# RL6678_IP_SVD register map
Vendor: Realtek
Registers are 32-bit, read-write, reset 0x0 unless marked. A register's access mark holds for its fields unless they carry their own. Offsets are from the block's base; [hi:lo] are bit positions; {n}, {i} and the like mark numbered series.

## PAGE0
Base 0x40000000
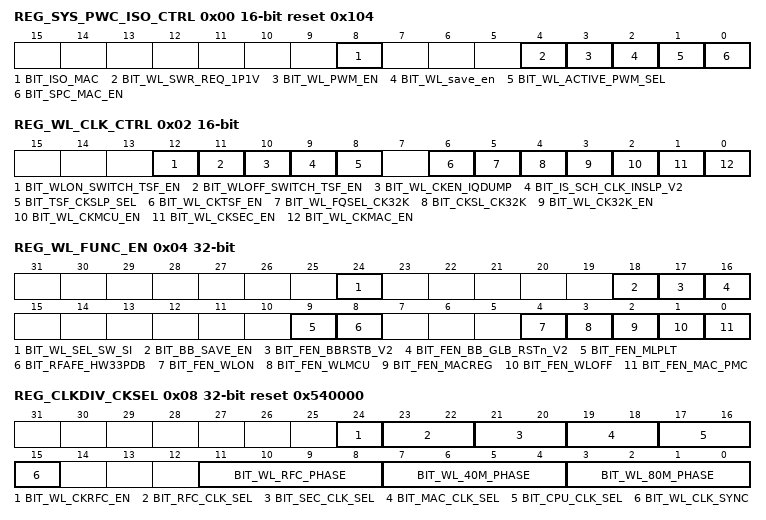
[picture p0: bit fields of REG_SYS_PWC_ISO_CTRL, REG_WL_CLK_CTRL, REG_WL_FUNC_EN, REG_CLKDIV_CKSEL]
0x00 REG_SYS_PWC_ISO_CTRL 16-bit reset 0x104
  [8] BIT_ISO_MAC — Isolation control for MAC, 1: isolation; 0: attach
  [4] BIT_WL_SWR_REQ_1P1V — 1: wl request switch SWR vlotage to 1.1V 0: wl request switch SWR vlotage to 0.9V
  [3] BIT_WL_PWM_EN — 1:WL request switch to PWM mode 0:WL request switch to PFM mode
  [2] BIT_WL_save_en — 1 to 0:gen req to restore register in power on flow 1:gen req to backup register in power on flow
  [1] BIT_WL_ACTIVE_PWM_SEL — ECO ADD. 1: wl request SWR PWM mode when eqit LPS
  [0] BIT_SPC_MAC_EN — 1: Enable WLOFF power cut
0x02 REG_WL_CLK_CTRL 16-bit access per field
  [12] BIT_WLON_SWITCH_TSF_EN rw — enable wlpmc switch TSF clock to MAC clock
  [11] BIT_WLOFF_SWITCH_TSF_EN rw — enable wlpmc switch TSF clock to 32K clock
  [10] BIT_WL_CKEN_IQDUMP rw — 0: disable clock for iqdump (LA MODE) 1: enable clock for iqdump (LA MODE) same clock source as security clock
  [9] BIT_IS_SCH_CLK_INSLP_V2 ro — WL TSF clock status: 0: MAC clock 1: 32K clock
  [8] BIT_TSF_CKSLP_SEL rw — 1: TSF clock switch to 32.768KHz; 0: TSF clock switch to MAC clock
  [6] BIT_WL_CKTSF_EN rw — 1: enable tsf clock; 0: gated
  [5] BIT_WL_FQSEL_CK32K rw — 1:32K frequency select 32.768KHz 0:32K frequency select 32KHz
  [4] BIT_CKSL_CK32K rw — 1:select MAC internal 32K clk, 0:select MAC external 32K clk
  [3] BIT_WL_CK32K_EN rw — 1: enable 32k clock; 0: gated
  [2] BIT_WL_CKMCU_EN rw — 1: enable MCU engine clock; 0: gated
  [1] BIT_WL_CKSEC_EN rw — 1: enable MAC security engine clock; 0: gated
  [0] BIT_WL_CKMAC_EN rw — 1: enable MAC clock; 0: gated
0x04 REG_WL_FUNC_EN access per field
  [24] BIT_WL_SEL_SW_SI rw — indicate SW use indirect path to access WLRFC register
  [18] BIT_BB_SAVE_EN rw — 1 to 0:gen req to restore register in power on flow 1:gen req to backup register in power on flow
  [17] BIT_FEN_BBRSTB_V2 rw — When this bit is set to "0", CCK and OFDM are disabled, and clock are gated. Otherwise, CCK and OFDM are enabled.
  [16] BIT_FEN_BB_GLB_RSTn_V2 rw — When this bit is set to "0", whole BB is reset. When this bit is set, BB is enabled.
  [9] BIT_FEN_MLPLT rw
  [8] BIT_RFAFE_HW33PDB rw
  [4] BIT_FEN_WLON rw — 1: enable WL partial ON; 0: reset
  [3] BIT_FEN_WLMCU rw — 1: enable WLMCU; 0: reset
  [2] BIT_FEN_MACREG rw — 1: enable MAC REG; 0: reset
  [1] BIT_FEN_WLOFF rw — 1: enable WLOFF; 0: reset
  [0] BIT_FEN_MAC_PMC rw — 1: enable MAC PMC; 0: reset
0x08 REG_CLKDIV_CKSEL reset 0x540000
  [24] BIT_WL_CKRFC_EN — 1: enable WLRFC clock; 0: gated
  [23:22] BIT_RFC_CLK_SEL — 11/10:40M 01:80M 00:160M
  [21:20] BIT_SEC_CLK_SEL — 11/10:40M 01:80M 00:160M
  [19:18] BIT_MAC_CLK_SEL — 11/10:20M 01:40M 00:80M
  [17:16] BIT_CPU_CLK_SEL
  [15] BIT_WL_CLK_SYNC — 1: sync 40M/80M clock phase with PLL
  [11:8] BIT_WL_RFC_PHASE — 80M WLRFC clock phase control
  [7:4] BIT_WL_40M_PHASE — 40M MAC clock phase control
  [3:0] BIT_WL_80M_PHASE — 80M security clock phase control
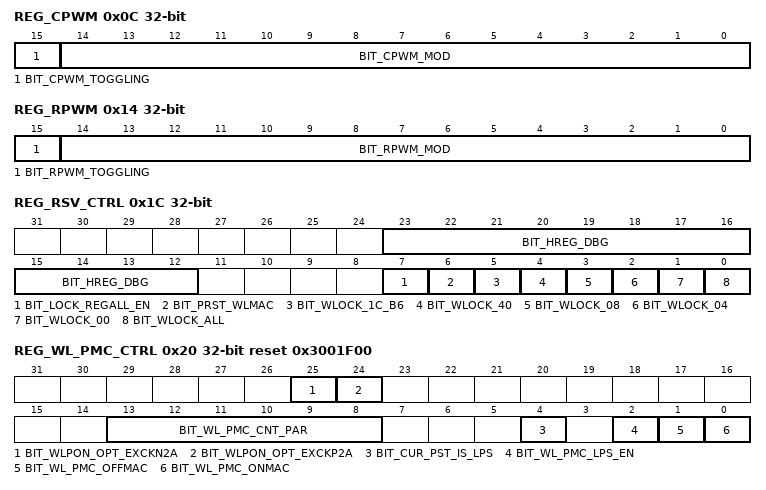
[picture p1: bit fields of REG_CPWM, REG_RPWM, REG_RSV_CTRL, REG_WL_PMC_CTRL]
0x0C REG_CPWM
  [15] BIT_CPWM_TOGGLING — Toggling bit : one bit sequence number bit. When this bit is toggled, interrupt is send to HISR.CPWMINT.
  [14:0] BIT_CPWM_MOD — The current power mode index.
0x14 REG_RPWM — register for hrpwm
  [15] BIT_RPWM_TOGGLING — Toggling bit : one bit sequence number bit. When this bit is toggled, interrupt is send to FISR.RPWMINT.
  [14:0] BIT_RPWM_MOD — The current power mode index.
0x1C REG_RSV_CTRL access per field
  [23:12] BIT_HREG_DBG ro — HREG Access Debug information
  [7] BIT_LOCK_REGALL_EN rw — 1:Enable 'Locked All' setting by Hardware, 0: Hardware Enable 'Locked All' denied.
  [6] BIT_PRST_WLMAC rw
  [5] BIT_WLOCK_1C_B6 rw — 1:Register Write Locked, 0: Register Accessible by SW/FW (offset:0x001C[6])
  [4] BIT_WLOCK_40 rw — 1:Register Write Locked, 0: Register Accessible by SW/FW (offset:0x0040h~0x0043h)
  [3] BIT_WLOCK_08 rw — 1:Register Write Locked, 0: Register Accessible by SW/FW (offset:0x0008h~0x000Bh)
  [2] BIT_WLOCK_04 rw — 1:Register Write Locked, 0: Register Accessible by SW/FW (offset:0x0004h~0x0007h)
  [1] BIT_WLOCK_00 rw — 1:Register Write Locked, 0: Register Accessible by SW/FW (offset:0x0000h~0x0003h)
  [0] BIT_WLOCK_ALL rw — 1:Register Write Locked, 0: Register Accessible by SW/FW (offset:0x0000h~0x00FFh)
0x20 REG_WL_PMC_CTRL access per field reset 0x3001F00
  [25] BIT_WLPON_OPT_EXCKN2A rw
  [24] BIT_WLPON_OPT_EXCKP2A rw — PON option to enable AFE clock
  [13:8] BIT_WL_PMC_CNT_PAR rw — WL PMC FSM counting unit.
  [4] BIT_CUR_PST_IS_LPS ro — indicate current WL power status is LPS mode
  [2] BIT_WL_PMC_LPS_EN rw — Inform WLAN PMC FSM to enter LPS mode. (auto clear when ready)
  [1] BIT_WL_PMC_OFFMAC rw — Inform WLAN PMC FSM to power OFF mode, include clock, isolation, power control for MAC only (clear when Power Ready)
  [0] BIT_WL_PMC_ONMAC rw — Inform WLAN PMC FSM to power On mode, include clock, isolation, power control for MAC only (clear when Power Ready)
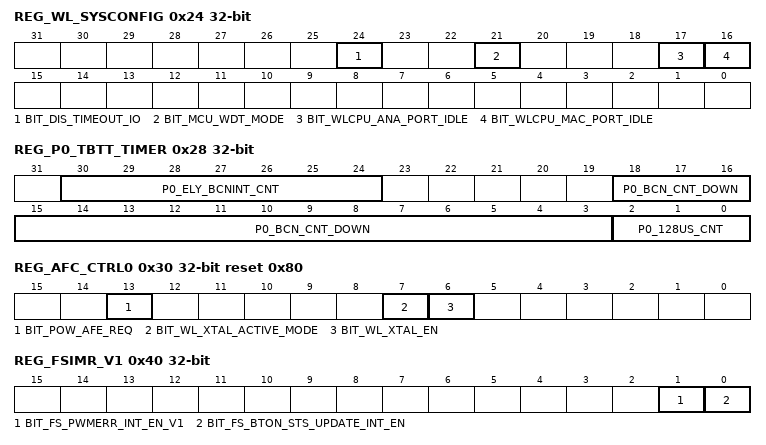
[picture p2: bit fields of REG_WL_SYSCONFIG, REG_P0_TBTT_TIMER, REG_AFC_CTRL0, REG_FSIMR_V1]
0x24 REG_WL_SYSCONFIG access per field
  [24] BIT_DIS_TIMEOUT_IO rw — Disabled timeout of IO wrapper
  [21] BIT_MCU_WDT_MODE rw
  [17] BIT_WLCPU_ANA_PORT_IDLE ro
  [16] BIT_WLCPU_MAC_PORT_IDLE ro
0x28 REG_P0_TBTT_TIMER ro
  [30:24] P0_ELY_BCNINT_CNT — Unit: bcn_space the total time to next specified TBTT is (new_ely_agg_cnt - 1) * r_bcn_space(0x554) + (beacon_cnt_down - 1)* 1ms + (cnt_128us + 1)* 128us
  [18:3] P0_BCN_CNT_DOWN — Unit: 1ms beacon_cnt_down - 1
  [2:0] P0_128US_CNT — Unit: 128us
0x30 REG_AFC_CTRL0 reset 0x80
  [13] BIT_POW_AFE_REQ — AFE power on request to afe_ctrl 1:request to turn on AFE pwr 0:turn off AFE pwr
  [7] BIT_WL_XTAL_ACTIVE_MODE — 1:WL request XTAL to enter active mode 0:WL request XTAL to enter LPS mode
  [6] BIT_WL_XTAL_EN — 1:WL enable XTAL 0:WL disable XTAL
0x40 REG_FSIMR_V1
  [1] BIT_FS_PWMERR_INT_EN_V1 — Enable MCU Access Error interrupt source(TIE0)
  [0] BIT_FS_BTON_STS_UPDATE_INT_EN — BTON status update interrupt When 0x78[31] toggled, this interrupt is issue to indicate the status updated.
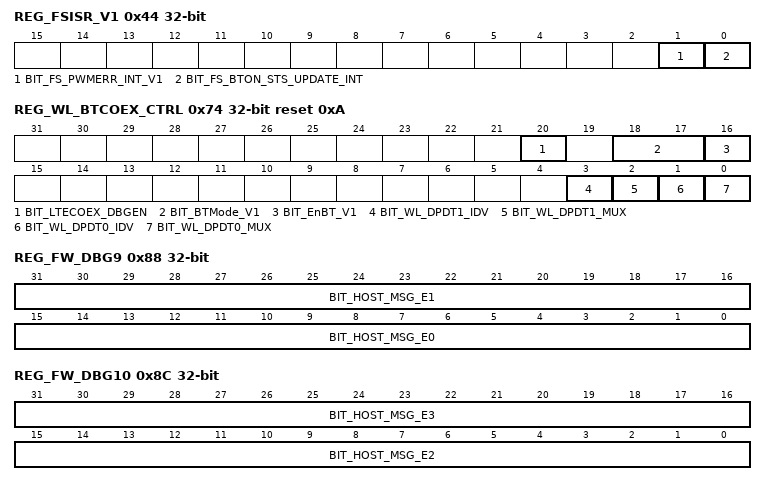
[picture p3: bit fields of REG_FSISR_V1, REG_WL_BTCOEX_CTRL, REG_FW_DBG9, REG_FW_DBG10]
0x44 REG_FSISR_V1 ro
  [1] BIT_FS_PWMERR_INT_V1 — MCU Access Error interrupt source Write 1 clear
  [0] BIT_FS_BTON_STS_UPDATE_INT — BTON status update interrupt When 0x78[31] toggled, this interrupt is issue to indicate the status updated.
0x48 TXDMA_H2C_RD_POINTER ro
  [17:0] tde_h2c_rd_addr — not used in amd2
0x4C TXDMA_H2C_WR_POINTER ro
  [17:0] tde_h2c_wr_addr — not used in amd2
{0x50+4i} REG_FW_DBG{i} (i=0..7)
  [31:0] BIT_FW_DBG{i} — fw debug{i}
0x70 REG_WL_PIN_FUNC_CTRL0
  [31:24] BIT_WL_DBG_SEL — WL debug select
0x74 REG_WL_BTCOEX_CTRL reset 0xA
  [20] BIT_LTECOEX_DBGEN
  [18:17] BIT_BTMode_V1 — Bluetooth Mode
  [16] BIT_EnBT_V1 — Enable PTA ( from BT side)
  [3] BIT_WL_DPDT1_IDV
  [2] BIT_WL_DPDT1_MUX
  [1] BIT_WL_DPDT0_IDV
  [0] BIT_WL_DPDT0_MUX
0x78 REG_SCOREBOARD_RD_BT2WL ro
  [30:0] BIT_RD_BT2WL_INFO — Read Data : WL TO BT INFO, WLON Status Report
0x7C REG_DBG_PORT_REG ro
  [31:0] BIT_DEBUG_ST — Debug signals, sel by 70[31:24]
0x80 REG_WL_MCUFW_CTRL
  [15] BIT_FW_INIT_RDY — CPU fw initialize ready, set by CPU
0x84 REG_FW_DBG8
  [31:0] BIT_BLK_TST — fw debug8
0x88 REG_FW_DBG9
  [31:16] BIT_HOST_MSG_E1 — User Defined Message
  [15:0] BIT_HOST_MSG_E0 — User Defined Message
0x8C REG_FW_DBG10
  [31:16] BIT_HOST_MSG_E3 — User Defined Message
  [15:0] BIT_HOST_MSG_E2 — User Defined Message
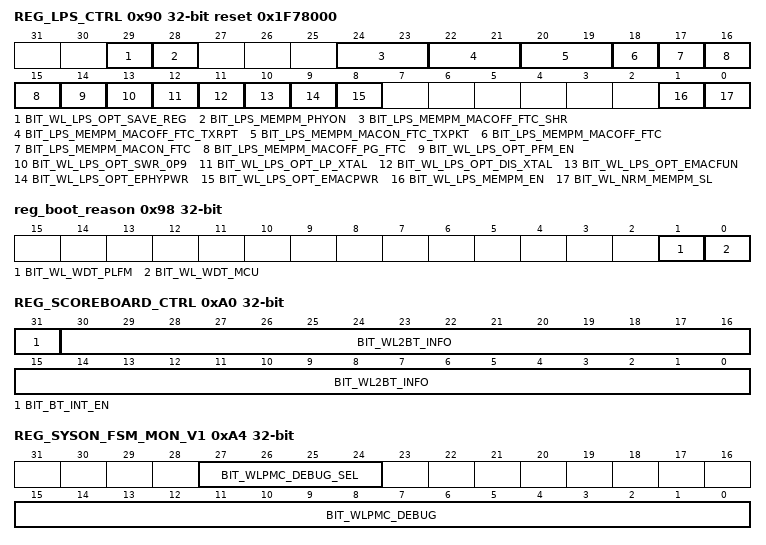
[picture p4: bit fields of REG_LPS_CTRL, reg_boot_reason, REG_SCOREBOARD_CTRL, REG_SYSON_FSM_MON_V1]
0x90 REG_LPS_CTRL access per field reset 0x1F78000
  [29] BIT_WL_LPS_OPT_SAVE_REG rw — LPS option to save retention FF 1: enable request to save retention FF 0: disable request to save retention FF
  [28] BIT_LPS_MEMPM_PHYON rw
  [24:23] BIT_LPS_MEMPM_MACOFF_FTC_SHR rw — MAC OFF FTC memory power mode when enable LPS memory power mode(for rxpktbuf/ txpktbuf low 24k[SHARE with system]) 00 : normal 01 : NAP 10 : RET 11 : SLP
  [22:21] BIT_LPS_MEMPM_MACOFF_FTC_TXRPT rw — MAC OFF FTC memory power mode when enable LPS memory power mode (for txrptbuf) 00 : normal 01 : NAP 10 : RET 11 : SLP
  [20:19] BIT_LPS_MEMPM_MACON_FTC_TXPKT rw — MAC ON FTC memory power mode when enable LPS memory power mode (for txpktbuf high 8k) 00 : normal 01 : NAP 10 : RET 11 : SLP
  [18] BIT_LPS_MEMPM_MACOFF_FTC rw — MAC OFF FTC memory power mode when enable LPS memory power mode (for txllt/rc4/txoqt/keysrch/rxfifo/txfifo/rxbacam/dmafifo/txpwr_rate/txpwr_macid/txpwr_usrlist/txpwr_srpwr/txpwr_rulim) 0 : normal 1 : NAP
  [17] BIT_LPS_MEMPM_MACON_FTC rw — MAC ON FTC memory power mode when enable LPS memory power mode(not used ) 0 : normal 1 : NAP
  [16:15] BIT_LPS_MEMPM_MACOFF_PG_FTC rw — MAC OFF FTC memory power mode when enable LPS memory power mode(for zgb_txbuf/zgb_rxbuf/rxcsibuf/phystsbuf) 00 : normal 01 : NAP 10 : RET 11 : SLP
  [14] BIT_WL_LPS_OPT_PFM_EN rw — LPS option to switch to PFM mode 1: set to PFM mode 0: stay in PWM mode
  [13] BIT_WL_LPS_OPT_SWR_0P9 rw — LPS option to set SWR voltage 0.9V 1: set SWR voltage 0.9V 0: set SWR voltage 1.1V
  [12] BIT_WL_LPS_OPT_LP_XTAL rw — LPS option to set XTAL low power mode when enable XTAL 1: set XTAL low power mode 0: set XTAL active mode
  [11] BIT_WL_LPS_OPT_DIS_XTAL rw — LPS option to disable XTAL 1: disable XTAL 0: enable XTAL
  [10] BIT_WL_LPS_OPT_EMACFUN rw — LPS option to reset WL MAC OFF block when enable WL MAC OFF power 1: not reset WL MAC OFF block 0: reset WL MAC OFF block
  [9] BIT_WL_LPS_OPT_EPHYPWR rw — LPS option to enable WL BB block power 1: Enable WL BB block power 0: Disable WL BB block power
  [8] BIT_WL_LPS_OPT_EMACPWR rw — LPS option to enable WL MAC OFF block power 1: Enable WL MAC OFF block power 0: Disable WL MAC OFF block power
  [1] BIT_WL_LPS_MEMPM_EN rw — enable LPS memory power mode control
  [0] BIT_WL_NRM_MEMPM_SL rw — MAC memory power mode when BIT_WL_LPS_MEMPM_EN is 0, 0 : Normal 1 : SD
0x94 REG_FW_DBG11
  [31:0] BIT_FW_DBG11 — fw debug11
0x98 reg_boot_reason
  [1] BIT_WL_WDT_PLFM, [0] BIT_WL_WDT_MCU
0xA0 REG_SCOREBOARD_CTRL access per field
  [31] BIT_BT_INT_EN wo — For WL, write 1 to issue interrupt 1 : Issue one INT to BT 0 : Don't care
  [30:0] BIT_WL2BT_INFO rw — WLON Status Report TO BTON
0xA4 REG_SYSON_FSM_MON_V1 access per field
  [27:24] BIT_WLPMC_DEBUG_SEL rw — debug select signal for WL PMC
  [15:0] BIT_WLPMC_DEBUG ro — debug signal of WL PMC
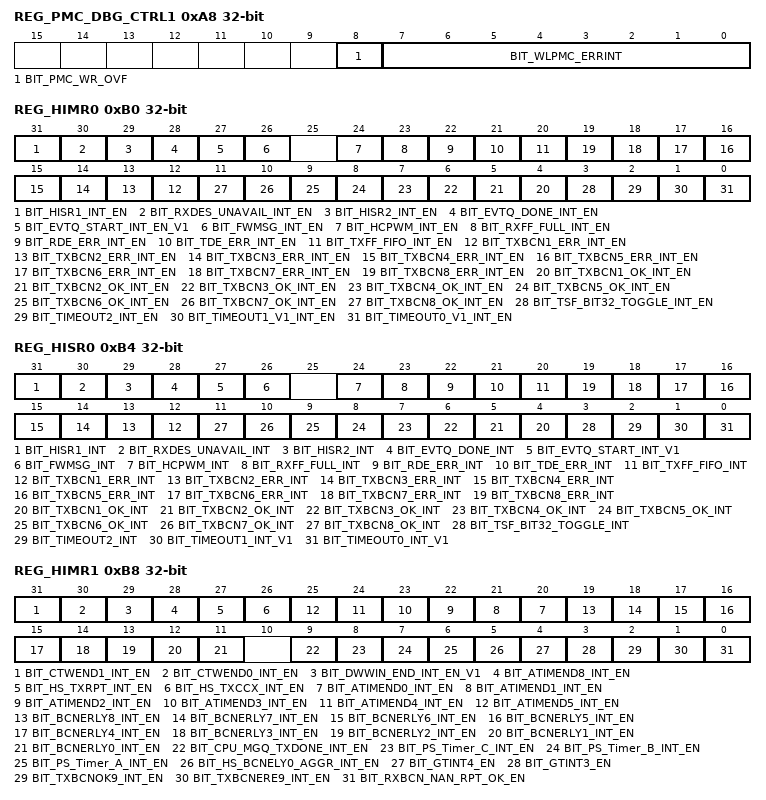
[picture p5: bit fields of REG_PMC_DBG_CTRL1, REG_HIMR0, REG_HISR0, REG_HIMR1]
0xA8 REG_PMC_DBG_CTRL1 ro
  [8] BIT_PMC_WR_OVF — PMC Write Access Timer Overflow
  [7:0] BIT_WLPMC_ERRINT — WLPMC Error interrupt
0xAC REG_PMC_DBG_CTRL2_V1
  [1:0] BIT_SYSON_REG_ARB — HW PMC Access Register Time Out Control
0xB0 REG_HIMR0
  [31] BIT_HISR1_INT_EN — HISR1 Indicator (HIISR1 andHIMR1 are true, this bit is set to 1)
  [30] BIT_RXDES_UNAVAIL_INT_EN — Rx Descriptor Unavailable
  [29] BIT_HISR2_INT_EN — HISR2 Indicator (HIISR2 andHIMR2 are true, this bit is set to 1)
  [28] BIT_EVTQ_DONE_INT_EN — event queue done interrupt for NAN
  [27] BIT_EVTQ_START_INT_EN_V1 — event queue start interrupt for NAN
  [26] BIT_FWMSG_INT_EN — FW message interrupt,CPU to Host Command INT Status, Write 1 clear
  [24] BIT_HCPWM_INT_EN — CPWM interrupt,CPU power Mode exchange INT Status, Write 1 clear
  [23] BIT_RXFF_FULL_INT_EN — Rxpktbuffer full interrupt
  [22] BIT_RDE_ERR_INT_EN — Rxdma error interrupt
  [21] BIT_TDE_ERR_INT_EN — Txdma error interrupt
  [20] BIT_TXFF_FIFO_INT_EN — txpktbuffer full interrupt
  [n+11] BIT_TXBCN{n}_ERR_INT_EN (n=1..8) — port0 BSSID{n-1} TX beacon error interrupt
  [n+3] BIT_TXBCN{n}_OK_INT_EN (n=1..8) — port0 BSSID{n-1} TX beacon ok interrupt
  [3] BIT_TSF_BIT32_TOGGLE_INT_EN — TSF Timer BIT32 toggle indication interrupt
  [2] BIT_TIMEOUT2_INT_EN — tsf Timer2 interrupt
  [1] BIT_TIMEOUT1_V1_INT_EN — tsf Timer1 interrupt
  [0] BIT_TIMEOUT0_V1_INT_EN — tsf Timer0 interrupt
0xB4 REG_HISR0 ro
  [31] BIT_HISR1_INT — HISR1 Indicator (HIISR1 andHIMR1 are true, this bit is set to 1)
  [30] BIT_RXDES_UNAVAIL_INT — Rx Descriptor Unavailable
  [29] BIT_HISR2_INT — HISR2 Indicator (HIISR2 andHIMR2 are true, this bit is set to 1)
  [28] BIT_EVTQ_DONE_INT — event queue done interrupt for NAN
  [27] BIT_EVTQ_START_INT_V1 — event queue start interrupt for NAN
  [26] BIT_FWMSG_INT — FW message interrupt,CPU to Host Command INT Status, Write 1 clear
  [24] BIT_HCPWM_INT — CPWM interrupt,CPU power Mode exchange INT Status, Write 1 clear
  [23] BIT_RXFF_FULL_INT — Rxpktbuffer full interrupt
  [22] BIT_RDE_ERR_INT — Rxdma error interrupt
  [21] BIT_TDE_ERR_INT — Txdma error interrupt
  [20] BIT_TXFF_FIFO_INT — txpktbuffer full interrupt
  [n+11] BIT_TXBCN{n}_ERR_INT (n=1..8) — port0 BSSID{n-1} TX beacon error interrupt
  [n+3] BIT_TXBCN{n}_OK_INT (n=1..8) — port0 BSSID{n-1} TX beacon ok interrupt
  [3] BIT_TSF_BIT32_TOGGLE_INT — TSF Timer BIT32 toggle indication interrupt
  [2] BIT_TIMEOUT2_INT — tsf Timer2 interrupt
  [1] BIT_TIMEOUT1_INT_V1 — tsf Timer1 interrupt
  [0] BIT_TIMEOUT0_INT_V1 — tsf Timer0 interrupt
0xB8 REG_HIMR1
  [31] BIT_CTWEND1_INT_EN — Client1 traffic window end interrupt for P2P
  [30] BIT_CTWEND0_INT_EN — Client0 traffic window end interrupt for P2P
  [29] BIT_DWWIN_END_INT_EN_V1 — discovery window end interrupt for NAN
  [28] BIT_ATIMEND8_INT_EN — port1 atimend interrupt
  [27] BIT_HS_TXRPT_INT_EN — TX report interrupt
  [26] BIT_HS_TXCCX_INT_EN — CCX PKT TX Report Interrupt
  [n+20] BIT_ATIMEND{n}_INT_EN (n=0..5) — port0 BSSID{n} atimend interrupt
  [19] BIT_BCNERLY8_INT_EN — port1 beacon early interrupt
  [18] BIT_BCNERLY7_INT_EN — port0 BSSID7 beacon early interrupt , only valid under MBSSID mode
  [17] BIT_BCNERLY6_INT_EN — port0 BSSID6 beacon early interrupt , only valid under MBSSID mode
  [16] BIT_BCNERLY5_INT_EN — port0 BSSID5 beacon early interrupt , only valid under MBSSID mode
  [15] BIT_BCNERLY4_INT_EN — port0 BSSID4 beacon early interrupt, only valid under MBSSID mode
  [14] BIT_BCNERLY3_INT_EN — port0 BSSID3 beacon early interrupt , only valid under MBSSID mode
  [13] BIT_BCNERLY2_INT_EN — port0 BSSID2 beacon early interrupt, only valid under MBSSID mode
  [12] BIT_BCNERLY1_INT_EN — port0 BSSID1 beacon early interrupt , only valid under MBSSID mode
  [11] BIT_BCNERLY0_INT_EN — This interrupt is issued at the time set by DRVERLYINT register before TBTT time for port 0 root bssid
  [9] BIT_CPU_MGQ_TXDONE_INT_EN — CPU_MQG_TXDONE ineterrupt source when HW TX CPUMGQ packet success, it issue interrupt to host
  [8] BIT_PS_Timer_C_INT_EN — PS_Timer_C interrupt source When the lower 4 bytes of TSF(that select by reg 0x1510[18:16]) matches the content of this register, the PS_Timer_C_INT interrupt is issued
  [7] BIT_PS_Timer_B_INT_EN — PS_Timer_B interrupt source When the lower 4 bytes of TSF(that select by reg 0x1510[10:8]) matches the content of this register, the PS_Timer_B_INT interrupt is issued
  [6] BIT_PS_Timer_A_INT_EN — PS_Timer_A interrupt source When the lower 4 bytes of TSF(that select by reg 0x1510[2:0]) matches the content of this register, the PS_Timer_A_INT interrupt is issued
  [5] BIT_HS_BCNELY0_AGGR_INT_EN — port 0 Beacon early aggregation interrupt
  [4] BIT_GTINT4_EN — When GTIMER4 expires, this bit is set to 1
  [3] BIT_GTINT3_EN — When GTIMER3 expires, this bit is set to 1
  [2] BIT_TXBCNOK9_INT_EN — PORT1 TX beacon OK interrupt
  [1] BIT_TXBCNERE9_INT_EN — PORT1 TX beacon Error interrupt
  [0] BIT_RXBCN_NAN_RPT_OK_EN — port2 rxbcn rpt and write to txrptbuf ok
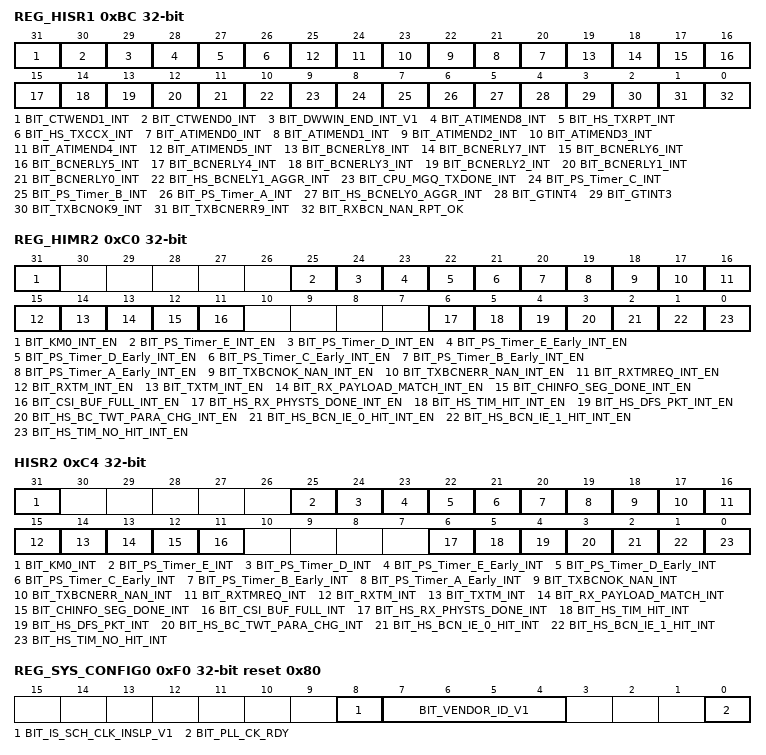
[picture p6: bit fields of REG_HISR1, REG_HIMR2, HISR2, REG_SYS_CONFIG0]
0xBC REG_HISR1 ro
  [31] BIT_CTWEND1_INT — Client1 traffic window end interrupt for P2P
  [30] BIT_CTWEND0_INT — Client0 traffic window end interrupt for P2P
  [29] BIT_DWWIN_END_INT_V1 — discovery window end interrupt for NAN
  [28] BIT_ATIMEND8_INT — port1 atimend interrupt
  [27] BIT_HS_TXRPT_INT — TX report interrupt
  [26] BIT_HS_TXCCX_INT — CCX PKT TX Report Interrupt
  [n+20] BIT_ATIMEND{n}_INT (n=0..5) — port0 BSSID{n} atimend interrupt
  [19] BIT_BCNERLY8_INT — port1 beacon early interrupt
  [18] BIT_BCNERLY7_INT — port0 BSSID7 beacon early interrupt , only valid under MBSSID mode
  [17] BIT_BCNERLY6_INT — port0 BSSID6 beacon early interrupt , only valid under MBSSID mode
  [16] BIT_BCNERLY5_INT — port0 BSSID5 beacon early interrupt , only valid under MBSSID mode
  [15] BIT_BCNERLY4_INT — port0 BSSID4 beacon early interrupt, only valid under MBSSID mode
  [14] BIT_BCNERLY3_INT — port0 BSSID3 beacon early interrupt , only valid under MBSSID mode
  [13] BIT_BCNERLY2_INT — port0 BSSID2 beacon early interrupt, only valid under MBSSID mode
  [12] BIT_BCNERLY1_INT — port0 BSSID1 beacon early interrupt , only valid under MBSSID mode
  [11] BIT_BCNERLY0_INT — This interrupt is issued at the time set by DRVERLYINT register before TBTT time for port 0 root bssid
  [10] BIT_HS_BCNELY1_AGGR_INT — port 1 Beacon early aggregation interrupt
  [9] BIT_CPU_MGQ_TXDONE_INT — CPU_MQG_TXDONE ineterrupt source when HW TX CPUMGQ packet success, it issue interrupt to host
  [8] BIT_PS_Timer_C_INT — PS_Timer_C interrupt source When the lower 4 bytes of TSF(that select by reg 0x1510[18:16]) matches the content of this register, the PS_Timer_C_INT interrupt is issued
  [7] BIT_PS_Timer_B_INT — PS_Timer_B interrupt source When the lower 4 bytes of TSF(that select by reg 0x1510[10:8]) matches the content of this register, the PS_Timer_B_INT interrupt is issued
  [6] BIT_PS_Timer_A_INT — PS_Timer_A interrupt source When the lower 4 bytes of TSF(that select by reg 0x1510[2:0]) matches the content of this register, the PS_Timer_A_INT interrupt is issued
  [5] BIT_HS_BCNELY0_AGGR_INT — port 0 Beacon early aggregation interrupt
  [4] BIT_GTINT4 — When GTIMER4 expires, this bit is set to 1
  [3] BIT_GTINT3 — When GTIMER3 expires, this bit is set to 1
  [2] BIT_TXBCNOK9_INT — PORT1 TX beacon OK interrupt
  [1] BIT_TXBCNERR9_INT — PORT1 TX beacon Error interrupt
  [0] BIT_RXBCN_NAN_RPT_OK — port2 rxbcn rpt and write to txrptbuf ok
0xC0 REG_HIMR2
  [31] BIT_KM0_INT_EN — The gathering of interrupts of KM0
  [25] BIT_PS_Timer_E_INT_EN — PS_Timer_E interrupt When the TSF(that select by reg 0x1520[13:12]) matches the content of this register, the PS_Timer_E_INT interrupt is issued
  [24] BIT_PS_Timer_D_INT_EN — PS_Timer_D interrupt When the lower 4 bytes of TSF(that select by reg 0x1520[17:16]) matches the content of this register, the PS_Timer_D_INT interrupt is issued
  [23] BIT_PS_Timer_E_Early_INT_EN — This interrupt is issued at the time set by PS_Timer_E_Early register before PS_Timer_E time.
  [22] BIT_PS_Timer_D_Early_INT_EN — This interrupt is issued at the time set by PS_Timer_D_Early register before PS_Timer_D time.
  [21] BIT_PS_Timer_C_Early_INT_EN — This interrupt is issued at the time set by PS_Timer_C_Early register before PS_Timer_C time.
  [20] BIT_PS_Timer_B_Early_INT_EN — This interrupt is issued at the time set by PS_Timer_B_Early register before PS_Timer_B time.
  [19] BIT_PS_Timer_A_Early_INT_EN — This interrupt is issued at the time set by PS_Timer_A_Early register before PS_Timer_A time.
  [18] BIT_TXBCNOK_NAN_INT_EN — PORT2 TX beacon OK interrupt
  [17] BIT_TXBCNERR_NAN_INT_EN — PORT2 TX beacon Error interrupt
  [16] BIT_RXTMREQ_INT_EN — If BIT_RXTMREQ_INT_EN =1. When HW receive TMREQ packet, it will generate interrupt to firmware.
  [15] BIT_RXTM_INT_EN — If BIT_RXTM_INT_EN =1. When HW receive TM and transmit ACK frame successfully. It will generate interrupt to firmware.
  [14] BIT_TXTM_INT_EN — If BIT_TXTM_INT_EN =1. When HW transmit TM and receive ACK frame successfully. It will generate interrupt to firmware.
  [13] BIT_RX_PAYLOAD_MATCH_INT_EN — indicate rx payload content match
  [12] BIT_CHINFO_SEG_DONE_INT_EN — indicate one channel info segment is received ok
  [11] BIT_CSI_BUF_FULL_INT_EN — indicate channel info rxcsibuffer is full
  [6] BIT_HS_RX_PHYSTS_DONE_INT_EN — indicate physts is successfully write into physts_mem
  [5] BIT_HS_TIM_HIT_INT_EN — when my aid or aid is 0 (0x16DC[8]) or my bssid is in tim element,generate this interrupt
  [4] BIT_HS_DFS_PKT_INT_EN — enable interrupt when receiving dfs pkt and about to reach threshold of given pkt number or timeout
  [3] BIT_HS_BC_TWT_PARA_CHG_INT_EN — RX broadcast twt with parameter changing,notify fw to read twt report
  [2] BIT_HS_BCN_IE_0_HIT_INT_EN — rx bcn with ie0 hit
  [1] BIT_HS_BCN_IE_1_HIT_INT_EN — rx bcn with ie1 hit
  [0] BIT_HS_TIM_NO_HIT_INT_EN — when no my aid or aid is 0(0x16DC[8]) or my bssid is not in tim element(0x16DB[31]),generate this interrupt
0xC4 HISR2 ro
  [31] BIT_KM0_INT — The gathering of interrupts of KM0
  [25] BIT_PS_Timer_E_INT — PS_Timer_E interrupt When the TSF(that select by reg 0x1520[13:12]) matches the content of this register, the PS_Timer_E_INT interrupt is issued
  [24] BIT_PS_Timer_D_INT — PS_Timer_D interrupt When the lower 4 bytes of TSF(that select by reg 0x1520[17:16]) matches the content of this register, the PS_Timer_D_INT interrupt is issued
  [23] BIT_PS_Timer_E_Early_INT — This interrupt is issued at the time set by PS_Timer_E_Early register before PS_Timer_E time.
  [22] BIT_PS_Timer_D_Early_INT — This interrupt is issued at the time set by PS_Timer_D_Early register before PS_Timer_D time.
  [21] BIT_PS_Timer_C_Early_INT — This interrupt is issued at the time set by PS_Timer_C_Early register before PS_Timer_C time.
  [20] BIT_PS_Timer_B_Early_INT — This interrupt is issued at the time set by PS_Timer_B_Early register before PS_Timer_B time.
  [19] BIT_PS_Timer_A_Early_INT — This interrupt is issued at the time set by PS_Timer_A_Early register before PS_Timer_A time.
  [18] BIT_TXBCNOK_NAN_INT — PORT2 TX beacon OK interrupt
  [17] BIT_TXBCNERR_NAN_INT — PORT2 TX beacon Error interrupt
  [16] BIT_RXTMREQ_INT — If BIT_RXTMREQ_INT_EN =1. When HW receive TMREQ packet, it will generate interrupt to firmware.
  [15] BIT_RXTM_INT — If BIT_RXTM_INT_EN =1. When HW receive TM and transmit ACK frame successfully. It will generate interrupt to firmware.
  [14] BIT_TXTM_INT — If BIT_TXTM_INT_EN =1. When HW transmit TM and receive ACK frame successfully. It will generate interrupt to firmware.
  [13] BIT_RX_PAYLOAD_MATCH_INT — indicate rx payload content match
  [12] BIT_CHINFO_SEG_DONE_INT — indicate one channel info segment is received ok
  [11] BIT_CSI_BUF_FULL_INT — indicate channel info rxcsibuffer is full
  [6] BIT_HS_RX_PHYSTS_DONE_INT — indicate physts is successfully write into physts_mem
  [5] BIT_HS_TIM_HIT_INT — when my aid or aid is 0 (0x16DC[8]) or my bssid is in tim element,generate this interrupt
  [4] BIT_HS_DFS_PKT_INT — enable interrupt when receiving dfs pkt and about to reach threshold of given pkt number or timeout
  [3] BIT_HS_BC_TWT_PARA_CHG_INT — RX broadcast twt with parameter changing,notify fw to read twt report
  [2] BIT_HS_BCN_IE_0_HIT_INT — rx bcn with ie0 hit
  [1] BIT_HS_BCN_IE_1_HIT_INT — rx bcn with ie1 hit
  [0] BIT_HS_TIM_NO_HIT_INT — when no my aid or aid is 0(0x16DC[8]) or my bssid is not in tim element(0x16DB[31]),generate this interrupt
0xE8 REG_SDM_IDR_CTRL0
  [5:0] BIT_SDM_ADDR — SDM register offset
0xEC REG_WL_CK32KGEN_RWD ro
  [31:0] BIT_CK32GEN_RD
0xF0 REG_SYS_CONFIG0 ro reset 0x80
  [8] BIT_IS_SCH_CLK_INSLP_V1 — WL TSF clock status: 0: MAC clock 1: 32K clock
  [7:4] BIT_VENDOR_ID_V1 — Vendor ID [7:6] : Download FW version ; 00: TSMC , 01: SMIC, 10: UMC [5] ; 0 : Download FW , init BB and RF registers 1 : Do not download FW and do not init BB and RF registers [4] ; 0 : BT do not exist in IC 1 : BT exist in IC
  [0] BIT_PLL_CK_RDY — indicate AFE PLL clock is ready
